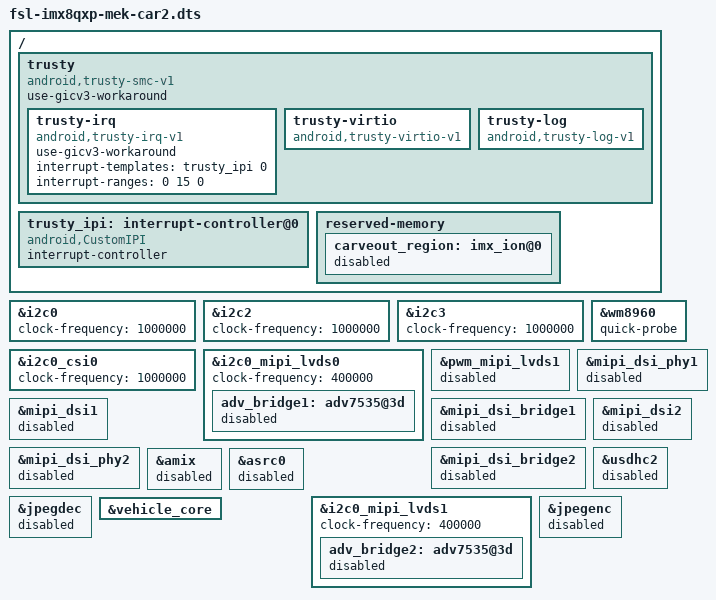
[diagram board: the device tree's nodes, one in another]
/*
 * Copyright 2018 NXP
 *
 * This program is free software; you can redistribute it and/or
 * modify it under the terms of the GNU General Public License
 * as published by the Free Software Foundation; either version 2
 * of the License, or (at your option) any later version.
 *
 * This program is distributed in the hope that it will be useful,
 * but WITHOUT ANY WARRANTY; without even the implied warranty of
 * MERCHANTABILITY or FITNESS FOR A PARTICULAR PURPOSE.  See the
 * GNU General Public License for more details.
 */

#include "fsl-imx8qxp-mek-rpmsg.dts"
/ {
	trusty {
		compatible = "android,trusty-smc-v1";
		ranges;
		#address-cells = <2>;
		#size-cells = <2>;
		use-gicv3-workaround;
		trusty-irq {
			use-gicv3-workaround;
			compatible = "android,trusty-irq-v1";
			interrupt-templates = <&trusty_ipi 0>;
			interrupt-ranges = < 0 15 0>;
		};
		trusty-virtio {
			compatible = "android,trusty-virtio-v1";
		};
		trusty-log {
			compatible = "android,trusty-log-v1";
		};
	};
	trusty_ipi: interrupt-controller@0 {
		compatible = "android,CustomIPI";
		interrupt-controller;
		#interrupt-cells = <1>;
	};
};

/ {
    reserved-memory {
            carveout_region: imx_ion@0 {
		    status = "disabled";
            };
    };
};

&i2c0 {
	clock-frequency = <1000000>;
};

&i2c2 {
	clock-frequency = <1000000>;
};

&i2c3 {
	clock-frequency = <1000000>;
};

&i2c0_csi0 {
	clock-frequency = <1000000>;
};

&i2c0_mipi_lvds0 {
	clock-frequency = <400000>;
	adv_bridge1: adv7535@3d {
		status = "disabled";
        };
};

&wm8960 {
	quick-probe;
};

&pwm_mipi_lvds1 {
	status = "disabled";
};

&mipi_dsi_phy1 {
        status = "disabled";
};

&mipi_dsi1 {
        status = "disabled";
};

&mipi_dsi_bridge1 {
        status = "disabled";
};

&mipi_dsi_phy2 {
   status = "disabled";
};

&mipi_dsi2 {
   status = "disabled";
};

&mipi_dsi_bridge2 {
   status = "disabled";
};

&usdhc2 {
   status = "disabled";
};

&amix {
   status = "disabled";
};

&asrc0 {
   status = "disabled";
};

&i2c0_mipi_lvds1 {
	clock-frequency = <400000>;
	adv_bridge2: adv7535@3d {
		status = "disabled";
        };
};

&jpegdec {
	status = "disabled";
};

&jpegenc {
	status = "disabled";
};

&vehicle_core {
	status = "okay";
};
